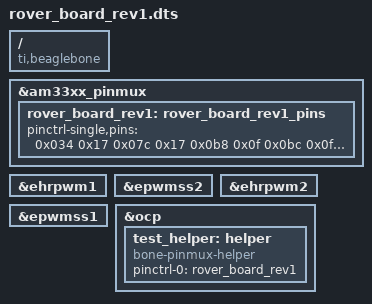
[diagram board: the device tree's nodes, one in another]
/*
* Copyright (C) 2012 Texas Instruments Incorporated - http:www.ti.com/
*
* This program is free software; you can redistribute it and/or modify
* it under the terms of the GNU General Public License version 2 as
* published by the Free Software Foundation.
*/
/dts-v1/;
/plugin/;

/ { compatible = "ti,beaglebone", "ti,beaglebone-black";
    fragment@0 {
        target = <&am33xx_pinmux>;
        __overlay__ {
            rover_board_rev1: rover_board_rev1_pins {
                pinctrl-single,pins = <
                /* MOTOR SHARED PINS */
                        0x034 0x17 /* Drive Sleep  */
                        0x07c 0x17 /* Drive Reset */
                        0x0b8 0x0f /* Treat Motor IN2/Camera Motor AIN2 */
                        0x0bc 0x0f /* Motor Decay */
                        0x0b4 0x0f /* Treat Motor I1/Camera Motor AI0 */
                        0x0a8 0x0f /* Treat Motor I2/Camera Motor AI1 */
                        0x0ac 0x0f /* Treat Motor I3/Camera Motor BI0 */
                        0x0a0 0x0f /* Treat Motor I4/Camera Motor BI1 */
                        0x0a4 0x13 /* P8_46 MODE4 ehrpwm2B PWM */ /*NOT GPIO “P8.46”, // Treat Motor IN1/Camera Motor AIN1 */

                /* DRIVE MOTOR A */
                        0x0c8 0x02 /* P8_36 MODE4 ehrpwm1A PWM *//* NOT GPIO "P8.36", // Drive A IN 1 */
                        0x0e0 0x0f /* Drive A IN 2 */
                        0x0e8 0x0f /* Drive A I0 */
                        0x0ec 0x0f /* Drive A I1 */
                        0x0e4 0x0f /* Drive A I2 */
                        0x0d8 0x0f /* Drive A I3 */
                        0x0cc 0x0f /* Drive A I4 */
                        /*0x000 0x37 NOTE COMMENTING OUT DUE TO CONFLICT*/ /* Drive A Fault */
                        /* SHARED  Drive A Sleep */
                        /* SHARED  Drive A Reset */
                        /* SHARED  Drive A Decay */
                        
                /* DRIVE MOTOR B */
                        0x020 0x14 /* P8_46 MODE4 ehrpwm2A PWM */ /*NOT GPIO “P8.19”, //Drive B IN1 */
                        0x038 0x0f /* Drive B IN2 */
                        0x030 0x0f /* Drive B I0 */
                        0x024 0x0f /* Drive B I2 */
                        0x028 0x0f /* Drive B I1 */
                        0x03c 0x0f /* Drive B I3 */
                        0x02c 0x0f /* Drive B I4 */
                        0x09c 0x37 /* Drive B Fault */
                        /* SHARED  Drive B Sleep */
                        /* SHARED  Drive B Reset */
                        /* SHARED  Drive B Decay */

                /* DRIVE MOTOR TREAT */
                        /* SHARED NOT GPIO Treat Motor IN1 */
                        /* SHARED Treat Motor IN2 */
                        0x0b0 0x0f /* Treat Motor I0 */
                        /* SHARED Treat Motor I1 */
                        /* SHARED Treat Motor I2 */
                        /* SHARED Treat Motor I3 */
                        /* SHARED Treat Motor I4 */
                        0x0d0 0x17 /* Treat Motor Reset */
                        0x0c0 0x37 /* Treat Motor Fault */
                        0x0c4 0x17 /* Treat Motor Sleep */
                        /* SHARED  Treat Motor  Decay */

                /* CAM MOTOR */
                        0x04c 0x16 /* P9_16 MODE4 ehrpwm1B PWM */ /* NOT GPIO "P9.16", // Camera Motor B IN 1 */
                        0x070 0x0f /* Camera Motor B IN 2 */
                        /* SHARED  Camera A IN 1  */
                        /* SHARED  Camera A IN 2 */
                        /* SHARED  Camera A I0 */
                        /* SHARED  Camera A I1 */
                        /* SHARED  Camera B I0 */
                        /* SHARED  Camera B I1  */
                        0x094 0x37 /* Camera Motor Fault */
                        0x098 0x17 /* Camera Motor Sleep */
                        0x074 0x17 /* Camera Motor Reset */

                /* WIFI */
                        0x078 0x0f /* Wifi HIB */
                        0x040 0x17 /* Wifi Reset */
                        /* NOT GPIO "P9.28", // Wifi SPI CS */
                        /* NOT GPIO "P9.29", // Wifi SPI MISO */
                        /* NOT GPIO "P9.30", // Wifi SPI MOSI */
                        /* NOT GPIO "P9.31", // Wifi SPI CLK */
                        /*0x1b4 0x0f NOTE COMMENTED OUT DUE TO CONFLICT*/ /* Wifi Host Interrupt  */

                /* 3V3 REGULATOR */
                        0x184 0x07 /* 3V3 SW EN */
                        0x1ac 0x07 /* 3V3 SW EN2 */
                        0x1a4 0x07 /* 3V3 REG EN */

                /*12V REGULATOR */
                        0x180 0x07 /* 12V REG EN */

                /* FUEL GAUGE */
                        /* NOT GPIO FUEL SCL */
                        /* NOT GPIO FUEL SDA */
                        /* ERROR - NOT GPIO"P9.32", // FUEL ALCC */

                /* SENSORS */
                        0x048 0x2f /* Cam Limit Switch 1 */
                        /*0x17c 0x2f NOTE COMMENTED OUT BECAUSE OF CONFLICT WITH I2C2 Cam Limit Switch 2 */
                        /*0x178 0x2f NOTE COMMENTED OUT BECAUSE OF CONFLICT WITH I2C2 Treat Position Sensor 1 */
                        0x154 0x2f /* Treat Position Sensor 2 */
                        0x150 0x2f /* Treat Position Sensor 3 */
                        0x044 0x0f /*  Charger Connected Detection */

                        /* NOT GPIO "P9.40", //  Treat count ADC 1 */
                        /* NOT GPIO "P9.39", //  Treat count ADC 2 */
                        /* NOT GPIO "P9.38", //  Treat count ADC 3 */
                        /* NOT GPIO "P9.37", //  Treat count ADC 4 */
                        /* NOT GPIO "P9.42", //  Extra ADC */
                >;
            };
        };
    };

    fragment@1 {
    target = <&ehrpwm1>;
    __overlay__ {
    status = "okay";
    };
    };

    fragment@2 {
    target = <&epwmss2>;
    __overlay__ {
    status = "okay";
    };
    };

    fragment@3 {
    target = <&ehrpwm2>;
    __overlay__ {
    status = "okay";
    };
    };

    fragment@4 {
    target = <&epwmss1>;
    __overlay__ {
    status = "okay";
    };
    };

    fragment@5 {
        target = <&ocp>;
        __overlay__ {
            test_helper: helper {
                compatible = "bone-pinmux-helper";
                pinctrl-names = "default";
                pinctrl-0 = <&rover_board_rev1>;
                status = "okay";
            };
        };
    };
};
